# HDSC_HC32F003 register map
Vendor: HDSC Co.Ltd; Series: ARMCM0P; File version: 1.2
CPU: CM0 r0p0, little endian, no MPU, no FPU, 3 interrupt priority bits
Registers are 32-bit, read-write, reset 0x0 unless marked. A register's access mark holds for its fields unless they carry their own. Offsets are from the block's base; [hi:lo] are bit positions; {n}, {i} and the like mark numbered series; 'fields as' and 'values as' point back to an identical list.

## BGR
Base 0x40002400; alternate view of ADC
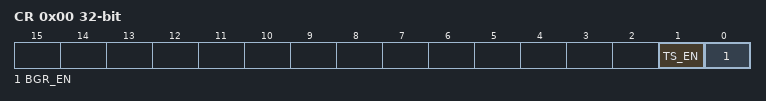
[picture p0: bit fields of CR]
0x00 CR
  [1] TS_EN, [0] BGR_EN

## BT0 — desc BT
Base 0x40000C00
Same registers: BT1 0x40000C20, BT2 0x40000C40
0x00 ARR (reset mask 0xFF)
  [15:0] ARR
0x04 CNT (reset mask 0xFF)
  [15:0] CNT
0x08 CNT32
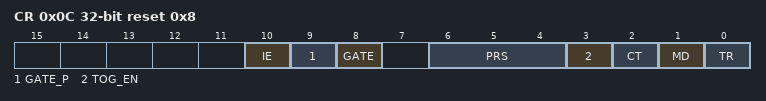
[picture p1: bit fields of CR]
0x0C CR reset 0x8
  [10] IE, [9] GATE_P, [8] GATE, [6:4] PRS, [3] TOG_EN, [2] CT, [1] MD, [0] TR
0x10 IFR ro
  [0] TF
0x14 ICLR wo reset 0x1
  [0] TFC

## CLK_TRIM
Base 0x40001800
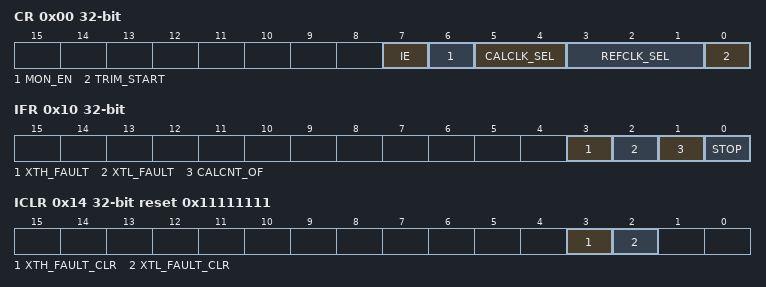
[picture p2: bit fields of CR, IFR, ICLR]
0x00 CR
  [7] IE, [6] MON_EN, [5:4] CALCLK_SEL, [3:1] REFCLK_SEL, [0] TRIM_START
0x04 REFCON
  [31:0] RCNTVAL
0x08 REFCNT ro
0x0C CALCNT ro
0x10 IFR ro
  [3] XTH_FAULT, [2] XTL_FAULT, [1] CALCNT_OF, [0] STOP
0x14 ICLR reset 0x11111111
  [3] XTH_FAULT_CLR, [2] XTL_FAULT_CLR
0x18 CALCON reset 0xFFFFFFFF
  [31:0] CCNTVAL

## CLOCK
Base 0x40002000
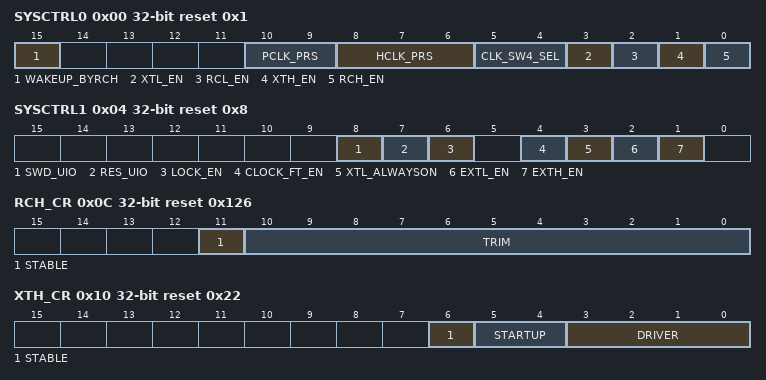
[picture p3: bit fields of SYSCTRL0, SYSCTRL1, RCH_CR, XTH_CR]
0x00 SYSCTRL0 reset 0x1
  [15] WAKEUP_BYRCH, [10:9] PCLK_PRS, [8:6] HCLK_PRS, [5:4] CLK_SW4_SEL, [3] XTL_EN, [2] RCL_EN, [1] XTH_EN, [0] RCH_EN
0x04 SYSCTRL1 reset 0x8
  [8] SWD_UIO, [7] RES_UIO, [6] LOCK_EN, [4] CLOCK_FT_EN, [3] XTL_ALWAYSON, [2] EXTL_EN, [1] EXTH_EN
0x08 SYSCTRL2
  [15:0] SYSCTRL2
0x0C RCH_CR reset 0x126
  [11] STABLE ro, [10:0] TRIM
0x10 XTH_CR reset 0x22
  [6] STABLE ro, [5:4] STARTUP, [3:0] DRIVER
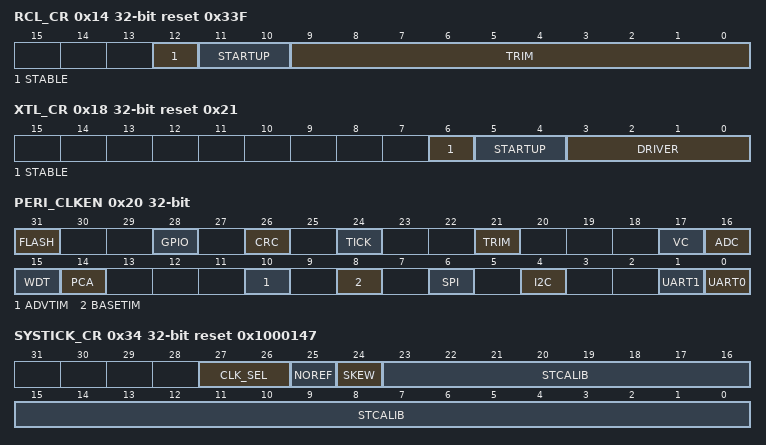
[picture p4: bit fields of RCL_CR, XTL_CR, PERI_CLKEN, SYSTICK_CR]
0x14 RCL_CR reset 0x33F
  [12] STABLE ro, [11:10] STARTUP, [9:0] TRIM
0x18 XTL_CR reset 0x21
  [6] STABLE ro, [5:4] STARTUP, [3:0] DRIVER
0x20 PERI_CLKEN
  [31] FLASH, [28] GPIO, [26] CRC, [24] TICK, [21] TRIM, [17] VC, [16] ADC, [15] WDT, [14] PCA, [10] ADVTIM, [8] BASETIM, [6] SPI, [4] I2C, [1] UART1, [0] UART0
0x34 SYSTICK_CR reset 0x1000147
  [27:26] CLK_SEL, [25] NOREF, [24] SKEW, [23:0] STCALIB
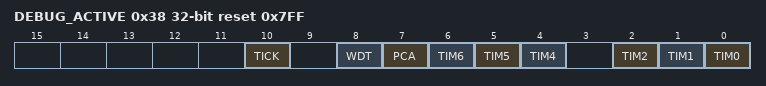
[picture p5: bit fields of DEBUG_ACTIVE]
0x38 DEBUG_ACTIVE reset 0x7FF
  [10] TICK, [8] WDT, [7] PCA, [6] TIM6, [5] TIM5, [4] TIM4, [2] TIM2, [1] TIM1, [0] TIM0

## CRC
Base 0x40020900
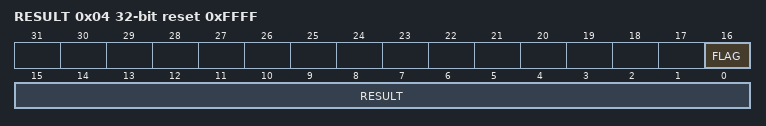
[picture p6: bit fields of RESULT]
0x04 RESULT reset 0xFFFF
  [16] FLAG ro, [15:0] RESULT
0x80 DATA wo

## FLASH
Base 0x40020000
0x00 TNVS reset 0x32
  [8:0] TNVS
0x04 TPGS reset 0x23
  [7:0] TPGS
0x08 TPROG reset 0x27
  [7:0] TPROG
0x0C TSERASE reset 0x18000
  [17:0] TSERASE
0x10 TMERASE reset 0x140000
  [20:0] TMERASE
0x14 TPRCV reset 0x24
  [11:0] TPRCV
0x18 TSRCV reset 0x240
  [11:0] TSRCV
0x1C TMRCV reset 0x1000
  [12:0] TMRCV
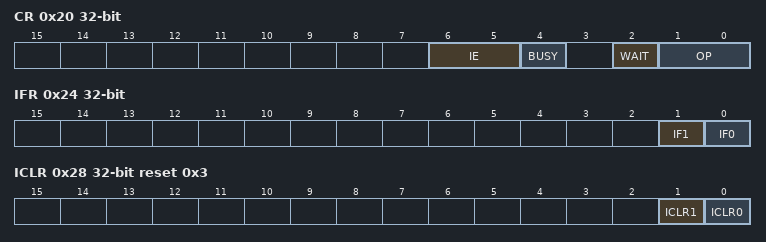
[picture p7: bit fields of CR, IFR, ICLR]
0x20 CR
  [6:5] IE, [4] BUSY ro, [2] WAIT, [1:0] OP
0x24 IFR ro
  [1] IF1, [0] IF0
0x28 ICLR wo reset 0x3
  [1] ICLR1, [0] ICLR0
0x2C BYPASS wo
  [15:0] BYSEQ
0x30 SLOCK
  [15:0] SLOCK

## GPIO
Base 0x40020C00
{0x0+4i} P{i:02}_SEL (i=1..3)
  [2:0] SEL
0x50 P14_SEL
  [2:0] SEL
0x54 P15_SEL
  [2:0] SEL
{0x30+4i} P{i}_SEL (i=23..27)
  [2:0] SEL
{0x48+4i} P{i}_SEL (i=31..36)
  [2:0] SEL
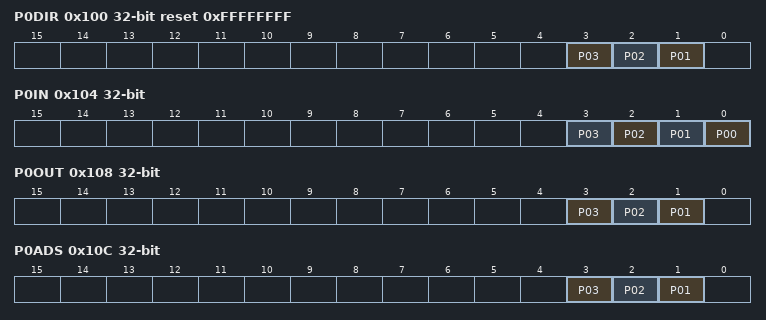
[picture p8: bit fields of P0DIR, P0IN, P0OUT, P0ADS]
0x100 P0DIR reset 0xFFFFFFFF
  [3] P03, [2] P02, [1] P01
0x104 P0IN ro
  [n] P{n:02} (n=0..3)
0x108 P0OUT
  [3] P03, [2] P02, [1] P01
0x10C P0ADS
  [3] P03, [2] P02, [1] P01
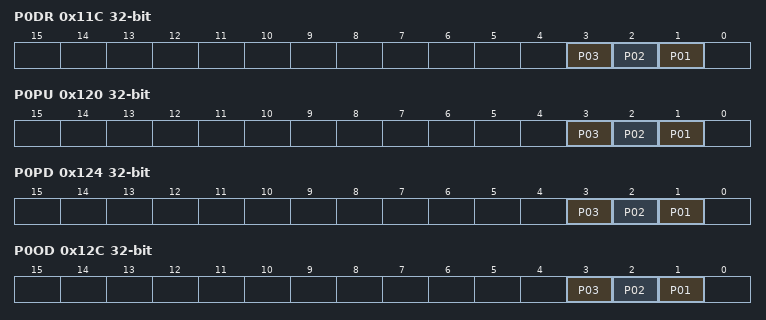
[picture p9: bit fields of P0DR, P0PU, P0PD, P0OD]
0x11C P0DR
  [3] P03, [2] P02, [1] P01
0x120 P0PU
  [3] P03, [2] P02, [1] P01
0x124 P0PD
  [3] P03, [2] P02, [1] P01
0x12C P0OD
  [3] P03, [2] P02, [1] P01
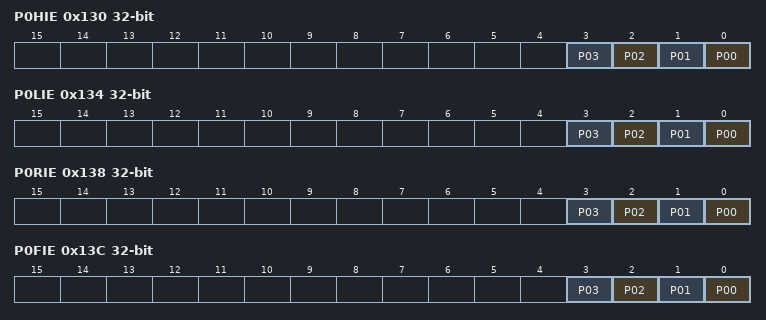
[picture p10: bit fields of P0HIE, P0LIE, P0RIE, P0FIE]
0x130 P0HIE ro
  [n] P{n:02} (n=0..3)
0x134 P0LIE ro
  [n] P{n:02} (n=0..3)
0x138 P0RIE ro
  [n] P{n:02} (n=0..3)
0x13C P0FIE ro
  [n] P{n:02} (n=0..3)
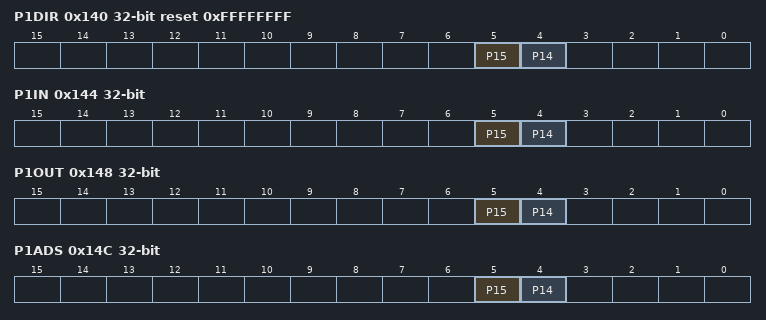
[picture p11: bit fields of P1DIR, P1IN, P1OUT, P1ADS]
0x140 P1DIR reset 0xFFFFFFFF
  [5] P15, [4] P14
0x144 P1IN ro (reset mask 0x3)
  [5] P15, [4] P14
0x148 P1OUT
  [5] P15, [4] P14
0x14C P1ADS
  [5] P15, [4] P14
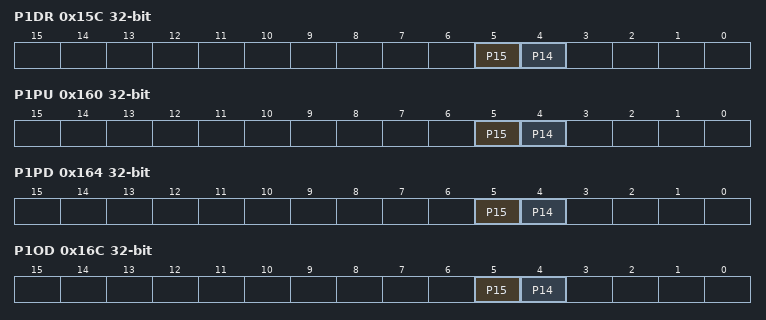
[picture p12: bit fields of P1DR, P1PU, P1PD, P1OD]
0x15C P1DR
  [5] P15, [4] P14
0x160 P1PU
  [5] P15, [4] P14
0x164 P1PD
  [5] P15, [4] P14
0x16C P1OD
  [5] P15, [4] P14
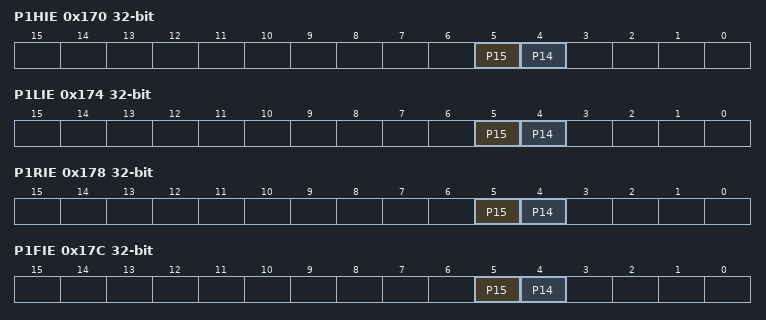
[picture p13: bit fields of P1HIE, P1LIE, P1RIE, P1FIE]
0x170 P1HIE ro (reset mask 0x3)
  [5] P15, [4] P14
0x174 P1LIE ro (reset mask 0x3)
  [5] P15, [4] P14
0x178 P1RIE ro (reset mask 0x3)
  [5] P15, [4] P14
0x17C P1FIE ro (reset mask 0x3)
  [5] P15, [4] P14
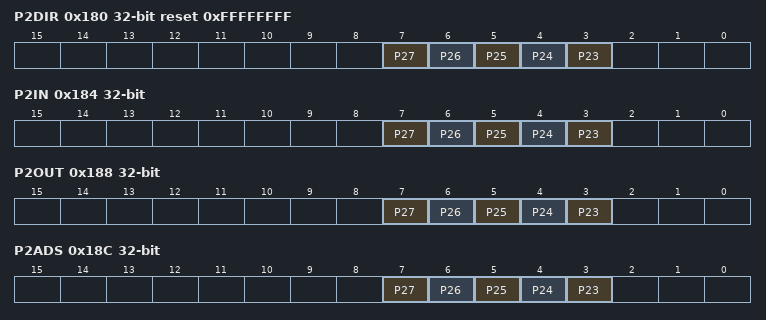
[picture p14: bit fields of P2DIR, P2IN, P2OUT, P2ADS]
0x180 P2DIR reset 0xFFFFFFFF
  [n-20] P{n} (n=23..27)
0x184 P2IN ro (reset mask 0x3)
  [n-20] P{n} (n=23..27)
0x188 P2OUT
  [n-20] P{n} (n=23..27)
0x18C P2ADS
  [n-20] P{n} (n=23..27)
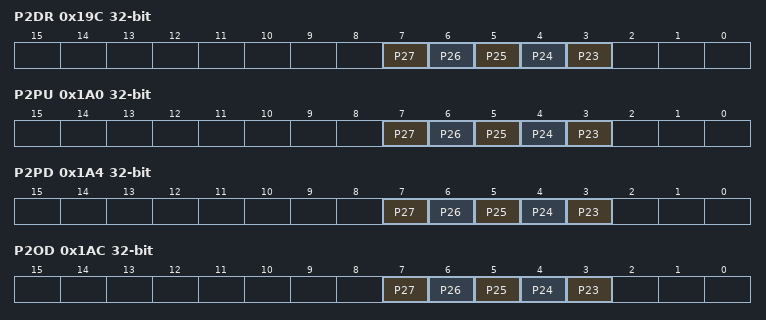
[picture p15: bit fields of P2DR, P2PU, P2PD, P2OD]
0x19C P2DR
  [n-20] P{n} (n=23..27)
0x1A0 P2PU
  [n-20] P{n} (n=23..27)
0x1A4 P2PD
  [n-20] P{n} (n=23..27)
0x1AC P2OD
  [n-20] P{n} (n=23..27)
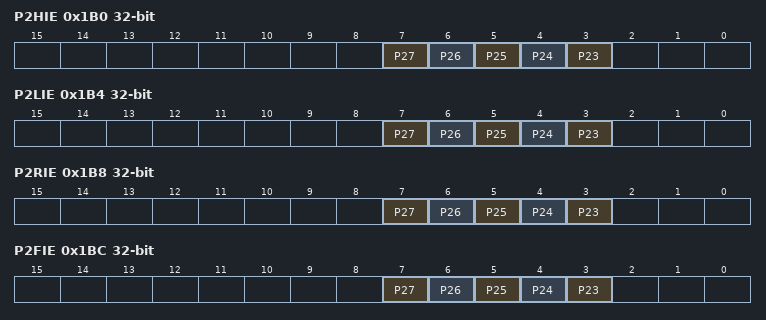
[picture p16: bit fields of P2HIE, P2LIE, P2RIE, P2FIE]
0x1B0 P2HIE ro (reset mask 0x3)
  [n-20] P{n} (n=23..27)
0x1B4 P2LIE ro (reset mask 0x3)
  [n-20] P{n} (n=23..27)
0x1B8 P2RIE ro (reset mask 0x3)
  [n-20] P{n} (n=23..27)
0x1BC P2FIE ro (reset mask 0x3)
  [n-20] P{n} (n=23..27)
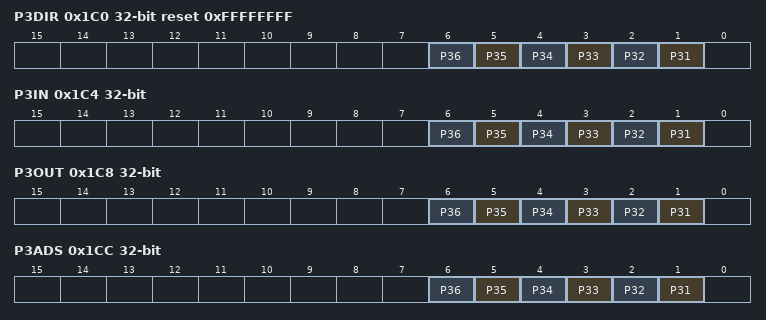
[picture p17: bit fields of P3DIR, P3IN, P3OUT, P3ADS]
0x1C0 P3DIR reset 0xFFFFFFFF
  [n-30] P{n} (n=31..36)
0x1C4 P3IN ro
  [n-30] P{n} (n=31..36)
0x1C8 P3OUT
  [n-30] P{n} (n=31..36)
0x1CC P3ADS
  [n-30] P{n} (n=31..36)
0x1DC P3DR
  [n-30] P{n} (n=31..36)
0x1E0 P3PU
  [n-30] P{n} (n=31..36)
0x1E4 P3PD
  [n-30] P{n} (n=31..36)
0x1EC P3OD
  [n-30] P{n} (n=31..36)
0x1F0 P3HIE ro
  [n-30] P{n} (n=31..36)
0x1F4 P3LIE ro
  [n-30] P{n} (n=31..36)
0x1F8 P3RIE ro
  [n-30] P{n} (n=31..36)
0x1FC P3FIE ro
  [n-30] P{n} (n=31..36)
0x200 P0STAT ro
  [n] P{n:02} (n=0..3)
0x210 P0ICLR ro
  [n] P{n:02} (n=0..3)
0x240 P1STAT ro (reset mask 0x3)
  [5] P15, [4] P14
0x250 P1ICLR ro (reset mask 0x3)
  [5] P15, [4] P14
0x280 P2STAT ro (reset mask 0x3)
  [n-20] P{n} (n=23..27)
0x290 P2ICLR ro (reset mask 0x3)
  [n-20] P{n} (n=23..27)
0x2C0 P3STAT ro
  [n-30] P{n} (n=31..36)
0x2D0 P3ICLR ro
  [n-30] P{n} (n=31..36)
0x300 CTRL0 reset 0x1
  [0] IESEL
0x304 CTRL1
  [14] IR_POL, [13] HCLK_EN, [12] PCLK_EN, [11:10] HCLK_SEL, [9:8] PCLK_SEL, [7:4] SSN_SEL, [3:0] EXT_CLK_SEL
0x308 CTRL2
  [2n+1:2n] PCA_CAP{n}_SEL (n=0..4)
0x30C CTRL3
  [11:10] TM6_A_SEL, [9:8] TM5_A_SEL, [7:6] TM4_A_SEL, [5:4] TM6_B_SEL, [3:2] TM5_B_SEL, [1:0] TM4_B_SEL
0x310 CTRL4
  [2n+1:2n] TM{n}_GATE_SEL (n=0..3)

## I2C
Base 0x40000400
0x00 TMRUN
  [0] TME
0x04 TM
  [7:0] TM
0x08 CR
  [6] ENS, [5] STA, [4] STO, [3] SI, [2] AA, [0] H1M
0x0C DATA
  [7:0] I2CDAT
0x10 ADDR
  [7:1] I2CADR, [0] GC
0x14 STAT ro
  [7:0] I2CSTA

## LVD
Base 0x40002400; alternate view of ADC
0x28 CR reset 0x100
  [15] IE, [14] HTEN, [13] RTEN, [12] FTEN, [11:9] DEBOUNCE_TIME, [8] FLTEN, [7:4] VTDS, [3:2] SOURCE_SEL, [1] ACT, [0] LVDEN
0x2C IFR
  [0] INTF

## PCA
Base 0x40001000
0x00 CCON
  [7] CF, [6] CR, [n] CCF{n} (n=0..4)
0x04 CMOD
  [7] CIDL, [6] WDTE, [3:1] CPS, [0] CFIE
0x08 CNT
  [15:0] CNT
0x0C ICLR wo reset 0x9F
  [7] CF, [n] CCF{n} (n=0..4)
{0x10+4i} CCAPM{i} (i=0..4)
  [6] ECOM, [5] CAPP, [4] CAPN, [3] MAT, [2] TOG, [1] PWM, [0] CCIE
{0x24+8i} CCAP{i}H (i=0..4)
  [7:0] CCAP{i}
{0x28+8i} CCAP{i}L (i=0..4)
  [7:0] CCAP{i}
0x4C CCAPO
  [n] CCAPO{n} (n=0..4)
{0x50+4i} CCAP{i} (i=0..4)
  [15:0] CCAP{i}

## RAM
Base 0x40020400
0x00 CR
  [1] IE, [0] CHKEN
0x04 ERRADDR ro
  [11:0] ERRADDR
0x08 IFR ro
  [0] ERR
0x0C ICLR ro
  [0] ERRCLR wo

## RESET
Base 0x4000201C
0x00 RESET_FLAG
  [7] RSTB, [6] SYSREQ, [5] LOCKUP, [4] PCA, [3] WDT, [2] LVD, [1] POR15, [0] POR5V
0x0C PREI_RESET reset 0xD7B3C757
  [28] GPIO, [26] CRC, [24] TICK, [21] TRIM, [17] VC, [16] ADC, [14] PCA, [10] ADVTIM, [8] BASETIM, [6] SPI, [4] I2C, [1] UART1, [0] UART0

## SPI
Base 0x40000800
0x00 CR
  [7] SPR2, [6] SPEN, [4] MSTR, [3] CPOL, [2] CPHA, [1] SPR1, [0] SPR0
0x04 SSN
  [0] SSN
0x08 STAT ro
  [7] SPIF, [6] WCOL, [5] SSERR, [4] MDF
0x0C DATA
  [7:0] SPDAT

## UART0 — desc UART
Base 0x40000000
Same registers: UART1 0x40000100
0x00 SBUF
  [7:0] SBUF
0x04 SCON
  [9] DBAUD, [7:6] SM01, [5] SM2, [4] REN, [3] TB8, [2] RB8, [1] TIEN, [0] RIEN
0x08 SADDR
  [7:0] SADDR
0x0C SADEN
  [7:0] SADEN
0x10 ISR ro
  [3] TE, [2] FE, [1] TI, [0] RI
0x14 ICR wo
  [2] FECLR, [1] TICLR rw, [0] RICLR rw

## VC
Base 0x40002400; alternate view of ADC
0x10 CR reset 0x20
  [15:14] VC1_HYS_SEL, [13:12] VC1_BIAS_SEL, [11:10] VC0_HYS_SEL, [9:8] VC0_BIAS_SEL, [7] REF2P5_SEL, [6] DIV_EN, [5:0] DIV
0x14 VC0_CR
  [15] IE, [14] LEVEL, [13] RISING, [12] FALLING, [11:9] DEBOUNCE_TIME, [8] FLTEN, [7:4] N_SEL, [3:1] P_SEL, [0] EN
0x18 VC1_CR
  fields as VC0_CR
0x1C VC0_OUT_CFG
  [15] BRAKE, [14] TM6, [13] INV_TIM6, [12] TM5, [11] INV_TIM5, [10] TM4, [9] INV_TIM4, [8] PCAECI, [7] PCACAP0, [6] INV_PCA, [3] TM2G, [2] TM1G, [1] TM0G, [0] INV_TIMER
0x20 VC1_OUT_CFG
  fields as VC0_OUT_CFG
0x24 IFR
  [3] VC1_FILTER ro, [2] VC0_FILTER ro, [1] VC1_INTF, [0] VC0_INTF

## WDT
Base 0x40000C00; alternate view of BT0
0x80 RST wo
  [7:0] WDTRST
0x84 CON reset 0xF
  [15:8] WCNTL ro, [7] WDINT ro, [5] WINT_EN, [4] WDTR ro, [3:0] WOV
